VERSION "0.6.1"

NS_ :

BS_:

BU_:

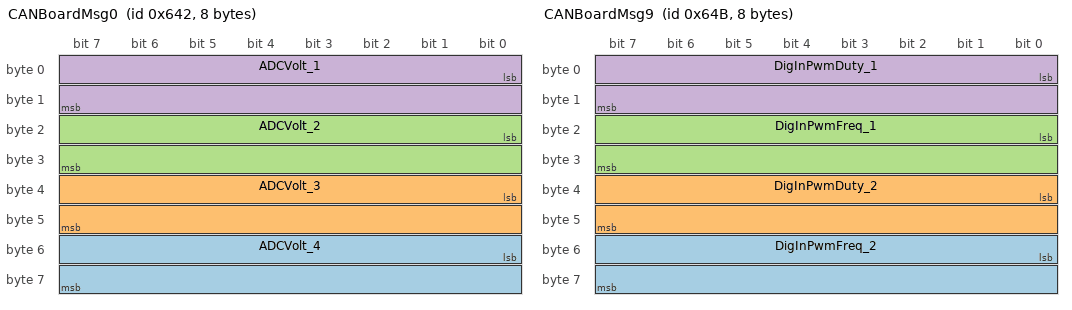
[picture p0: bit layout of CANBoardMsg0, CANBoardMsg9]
BO_ 1602 CANBoardMsg0: 8 Vector__XXX
 SG_ ADCVolt_4 : 48|16@1+ (0.001,0) [0|0] "" Vector__XXX
 SG_ ADCVolt_3 : 32|16@1+ (0.001,0) [0|0] "" Vector__XXX
 SG_ ADCVolt_2 : 16|16@1+ (0.001,0) [0|0] "" Vector__XXX
 SG_ ADCVolt_1 : 0|16@1+ (0.001,0) [0|0] "" Vector__XXX

BO_ 1603 CANBoardMsg1: 8 Vector__XXX
 SG_ BoardTemp : 48|16@1+ (1,0) [0|125] "" Vector__XXX
 SG_ ADCVolt5 : 0|16@1+ (0.001,0) [0|6] "" Vector__XXX

BO_ 1604 CANBoardMsg2: 8 Vector__XXX
 SG_ Heartbeat : 56|8@1+ (1,0) [0|255] "" Vector__XXX
 SG_ DigitalOutput_4 : 51|1@1+ (1,0) [0|0] "" Vector__XXX
 SG_ DigitalOutput_3 : 50|1@1+ (1,0) [0|0] "" Vector__XXX
 SG_ DigitalOutput_2 : 49|1@1+ (1,0) [0|0] "" Vector__XXX
 SG_ DigitalOutput_1 : 48|1@1+ (1,0) [0|0] "" Vector__XXX
 SG_ AnalogSwitch_5 : 44|1@1+ (1,0) [0|0] "" Vector__XXX
 SG_ AnalogSwitch_4 : 43|1@1+ (1,0) [0|0] "" Vector__XXX
 SG_ AnalogSwitch_3 : 42|1@1+ (1,0) [0|0] "" Vector__XXX
 SG_ AnalogSwitch_2 : 41|1@1+ (1,0) [0|0] "" Vector__XXX
 SG_ AnalogSwitch_1 : 40|1@1+ (1,0) [0|0] "" Vector__XXX
 SG_ DigitalInput_8 : 39|1@1+ (1,0) [0|0] "" Vector__XXX
 SG_ DigitalInput_7 : 38|1@1+ (1,0) [0|0] "" Vector__XXX
 SG_ DigitalInput_6 : 37|1@1+ (1,0) [0|0] "" Vector__XXX
 SG_ DigitalInput_5 : 36|1@1+ (1,0) [0|0] "" Vector__XXX
 SG_ DigitalInput_4 : 35|1@1+ (1,0) [0|0] "" Vector__XXX
 SG_ DigitalInput_3 : 34|1@1+ (1,0) [0|0] "" Vector__XXX
 SG_ DigitalInput_2 : 33|1@1+ (1,0) [0|0] "" Vector__XXX
 SG_ DigitalInput_1 : 32|1@1+ (1,0) [0|0] "" Vector__XXX
 SG_ Flash_4 : 27|1@1+ (1,0) [0|0] "" Vector__XXX
 SG_ Flash_3 : 26|1@1+ (1,0) [0|0] "" Vector__XXX
 SG_ Flash_2 : 25|1@1+ (1,0) [0|0] "" Vector__XXX
 SG_ Flash_1 : 24|1@1+ (1,0) [0|0] "" Vector__XXX
 SG_ RotarySwitch_5 : 16|4@1+ (1,0) [0|0] "" Vector__XXX
 SG_ RotarySwitch_4 : 12|4@1+ (1,0) [0|0] "" Vector__XXX
 SG_ RotarySwitch_3 : 8|4@1+ (1,0) [0|0] "" Vector__XXX
 SG_ RotarySwitch_2 : 4|4@1+ (1,0) [0|0] "" Vector__XXX
 SG_ RotarySwitch_1 : 0|4@1+ (1,0) [0|0] "" Vector__XXX

BO_ 1605 CANBoardMsg3: 8 Vector__XXX
 SG_ VirtualInput_16 : 47|1@1+ (1,0) [0|0] "" Vector__XXX
 SG_ VirtualInput_15 : 46|1@1+ (1,0) [0|0] "" Vector__XXX
 SG_ VirtualInput_14 : 45|1@1+ (1,0) [0|0] "" Vector__XXX
 SG_ VirtualInput_13 : 44|1@1+ (1,0) [0|0] "" Vector__XXX
 SG_ VirtualInput_12 : 43|1@1+ (1,0) [0|0] "" Vector__XXX
 SG_ VirtualInput_11 : 42|1@1+ (1,0) [0|0] "" Vector__XXX
 SG_ VirtualInput_10 : 41|1@1+ (1,0) [0|0] "" Vector__XXX
 SG_ VirtualInput_9 : 40|1@1+ (1,0) [0|0] "" Vector__XXX
 SG_ VirtualInput_8 : 39|1@1+ (1,0) [0|0] "" Vector__XXX
 SG_ VirtualInput_7 : 38|1@1+ (1,0) [0|0] "" Vector__XXX
 SG_ VirtualInput_6 : 37|1@1+ (1,0) [0|0] "" Vector__XXX
 SG_ VirtualInput_5 : 36|1@1+ (1,0) [0|0] "" Vector__XXX
 SG_ VirtualInput_4 : 35|1@1+ (1,0) [0|0] "" Vector__XXX
 SG_ VirtualInput_3 : 34|1@1+ (1,0) [0|0] "" Vector__XXX
 SG_ VirtualInput_2 : 33|1@1+ (1,0) [0|0] "" Vector__XXX
 SG_ VirtualInput_1 : 32|1@1+ (1,0) [0|0] "" Vector__XXX
 SG_ CANInput_32 : 31|1@1+ (1,0) [0|0] "" Vector__XXX
 SG_ CANInput_31 : 30|1@1+ (1,0) [0|0] "" Vector__XXX
 SG_ CANInput_30 : 29|1@1+ (1,0) [0|0] "" Vector__XXX
 SG_ CANInput_29 : 28|1@1+ (1,0) [0|0] "" Vector__XXX
 SG_ CANInput_28 : 27|1@1+ (1,0) [0|0] "" Vector__XXX
 SG_ CANInput_27 : 26|1@1+ (1,0) [0|0] "" Vector__XXX
 SG_ CANInput_26 : 25|1@1+ (1,0) [0|0] "" Vector__XXX
 SG_ CANInput_25 : 24|1@1+ (1,0) [0|0] "" Vector__XXX
 SG_ CANInput_24 : 23|1@1+ (1,0) [0|0] "" Vector__XXX
 SG_ CANInput_23 : 22|1@1+ (1,0) [0|0] "" Vector__XXX
 SG_ CANInput_22 : 21|1@1+ (1,0) [0|0] "" Vector__XXX
 SG_ CANInput_21 : 20|1@1+ (1,0) [0|0] "" Vector__XXX
 SG_ CANInput_20 : 19|1@1+ (1,0) [0|0] "" Vector__XXX
 SG_ CANInput_19 : 18|1@1+ (1,0) [0|0] "" Vector__XXX
 SG_ CANInput_18 : 17|1@1+ (1,0) [0|0] "" Vector__XXX
 SG_ CANInput_17 : 16|1@1+ (1,0) [0|0] "" Vector__XXX
 SG_ CANInput_16 : 15|1@1+ (1,0) [0|0] "" Vector__XXX
 SG_ CANInput_15 : 14|1@1+ (1,0) [0|0] "" Vector__XXX
 SG_ CANInput_14 : 13|1@1+ (1,0) [0|0] "" Vector__XXX
 SG_ CANInput_13 : 12|1@1+ (1,0) [0|0] "" Vector__XXX
 SG_ CANInput_12 : 11|1@1+ (1,0) [0|0] "" Vector__XXX
 SG_ CANInput_11 : 10|1@1+ (1,0) [0|0] "" Vector__XXX
 SG_ CANInput_10 : 9|1@1+ (1,0) [0|0] "" Vector__XXX
 SG_ CANInput_9 : 8|1@1+ (1,0) [0|0] "" Vector__XXX
 SG_ CANInput_8 : 7|1@1+ (1,0) [0|0] "" Vector__XXX
 SG_ CANInput_7 : 6|1@1+ (1,0) [0|0] "" Vector__XXX
 SG_ CANInput_6 : 5|1@1+ (1,0) [0|0] "" Vector__XXX
 SG_ CANInput_5 : 4|1@1+ (1,0) [0|0] "" Vector__XXX
 SG_ CANInput_4 : 3|1@1+ (1,0) [0|0] "" Vector__XXX
 SG_ CANInput_3 : 2|1@1+ (1,0) [0|0] "" Vector__XXX
 SG_ CANInput_2 : 1|1@1+ (1,0) [0|0] "" Vector__XXX
 SG_ CANInput_1 : 0|1@1+ (1,0) [0|0] "" Vector__XXX

BO_ 1606 CANBoardMsg4: 8 Vector__XXX
 SG_ ConditionResult_32 : 63|1@1+ (1,0) [0|0] "" Vector__XXX
 SG_ ConditionResult_31 : 62|1@1+ (1,0) [0|0] "" Vector__XXX
 SG_ ConditionResult_30 : 61|1@1+ (1,0) [0|0] "" Vector__XXX
 SG_ ConditionResult_29 : 60|1@1+ (1,0) [0|0] "" Vector__XXX
 SG_ ConditionResult_28 : 59|1@1+ (1,0) [0|0] "" Vector__XXX
 SG_ ConditionResult_27 : 58|1@1+ (1,0) [0|0] "" Vector__XXX
 SG_ ConditionResult_26 : 57|1@1+ (1,0) [0|0] "" Vector__XXX
 SG_ ConditionResult_25 : 56|1@1+ (1,0) [0|0] "" Vector__XXX
 SG_ ConditionResult_24 : 55|1@1+ (1,0) [0|0] "" Vector__XXX
 SG_ ConditionResult_23 : 54|1@1+ (1,0) [0|0] "" Vector__XXX
 SG_ ConditionResult_22 : 53|1@1+ (1,0) [0|0] "" Vector__XXX
 SG_ ConditionResult_21 : 52|1@1+ (1,0) [0|0] "" Vector__XXX
 SG_ ConditionResult_20 : 51|1@1+ (1,0) [0|0] "" Vector__XXX
 SG_ ConditionResult_19 : 50|1@1+ (1,0) [0|0] "" Vector__XXX
 SG_ ConditionResult_18 : 49|1@1+ (1,0) [0|0] "" Vector__XXX
 SG_ ConditionResult_17 : 48|1@1+ (1,0) [0|0] "" Vector__XXX
 SG_ ConditionResult_16 : 47|1@1+ (1,0) [0|0] "" Vector__XXX
 SG_ ConditionResult_15 : 46|1@1+ (1,0) [0|0] "" Vector__XXX
 SG_ ConditionResult_14 : 45|1@1+ (1,0) [0|0] "" Vector__XXX
 SG_ ConditionResult_13 : 44|1@1+ (1,0) [0|0] "" Vector__XXX
 SG_ ConditionResult_12 : 43|1@1+ (1,0) [0|0] "" Vector__XXX
 SG_ ConditionResult_11 : 42|1@1+ (1,0) [0|0] "" Vector__XXX
 SG_ ConditionResult_10 : 41|1@1+ (1,0) [0|0] "" Vector__XXX
 SG_ ConditionResult_9 : 40|1@1+ (1,0) [0|0] "" Vector__XXX
 SG_ ConditionResult_8 : 39|1@1+ (1,0) [0|0] "" Vector__XXX
 SG_ ConditionResult_7 : 38|1@1+ (1,0) [0|0] "" Vector__XXX
 SG_ ConditionResult_6 : 37|1@1+ (1,0) [0|0] "" Vector__XXX
 SG_ ConditionResult_5 : 36|1@1+ (1,0) [0|0] "" Vector__XXX
 SG_ ConditionResult_4 : 35|1@1+ (1,0) [0|0] "" Vector__XXX
 SG_ ConditionResult_3 : 34|1@1+ (1,0) [0|0] "" Vector__XXX
 SG_ ConditionResult_2 : 33|1@1+ (1,0) [0|0] "" Vector__XXX
 SG_ ConditionResult_1 : 32|1@1+ (1,0) [0|0] "" Vector__XXX
 SG_ CounterValue_4 : 24|8@1+ (1,0) [0|0] "" Vector__XXX
 SG_ CounterValue_3 : 16|8@1+ (1,0) [0|0] "" Vector__XXX
 SG_ CounterValue_2 : 8|8@1+ (1,0) [0|0] "" Vector__XXX
 SG_ CounterValue_1 : 0|8@1+ (1,0) [0|0] "" Vector__XXX

BO_ 1607 CANBoardMsg5: 8 Vector__XXX
 SG_ CANInputValue_2 : 32|32@1- (1,0) [0|0] "" Vector__XXX
 SG_ CANInputValue_1 : 0|32@1- (1,0) [0|0] "" Vector__XXX

BO_ 1608 CANBoardMsg6: 8 Vector__XXX
 SG_ CANInputValue_4 : 32|32@1- (1,0) [0|0] "" Vector__XXX
 SG_ CANInputValue_3 : 0|32@1- (1,0) [0|0] "" Vector__XXX

BO_ 1609 CANBoardMsg7: 8 Vector__XXX
 SG_ CANInputValue_6 : 32|32@1- (1,0) [0|0] "" Vector__XXX
 SG_ CANInputValue_5 : 0|32@1- (1,0) [0|0] "" Vector__XXX

BO_ 1610 CANBoardMsg8: 8 Vector__XXX
 SG_ CANInputValue_8 : 32|32@1- (1,0) [0|0] "" Vector__XXX
 SG_ CANInputValue_7 : 0|32@1- (1,0) [0|0] "" Vector__XXX

BO_ 1611 CANBoardMsg9: 8 Vector__XXX
 SG_ DigInPwmFreq_2 : 48|16@1+ (0.1,0) [0|6553.5] "Hz" Vector__XXX
 SG_ DigInPwmDuty_2 : 32|16@1+ (0.01,0) [0|100] "%" Vector__XXX
 SG_ DigInPwmFreq_1 : 16|16@1+ (0.1,0) [0|6553.5] "Hz" Vector__XXX
 SG_ DigInPwmDuty_1 : 0|16@1+ (0.01,0) [0|100] "%" Vector__XXX

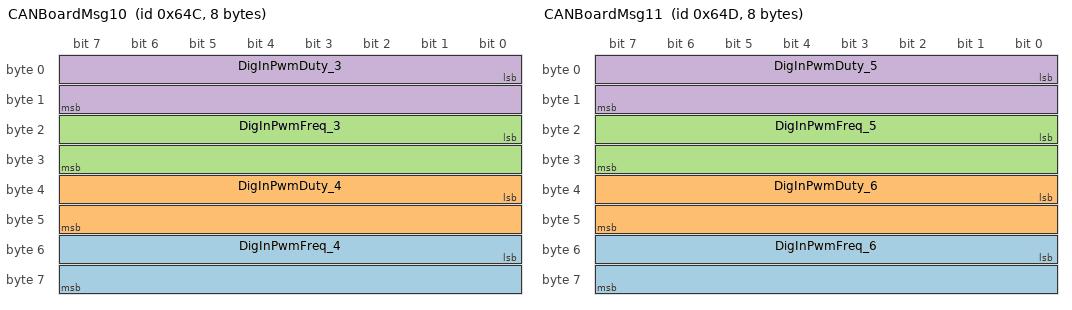
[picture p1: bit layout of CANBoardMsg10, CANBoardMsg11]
BO_ 1612 CANBoardMsg10: 8 Vector__XXX
 SG_ DigInPwmFreq_4 : 48|16@1+ (0.1,0) [0|6553.5] "Hz" Vector__XXX
 SG_ DigInPwmDuty_4 : 32|16@1+ (0.01,0) [0|100] "%" Vector__XXX
 SG_ DigInPwmFreq_3 : 16|16@1+ (0.1,0) [0|6553.5] "Hz" Vector__XXX
 SG_ DigInPwmDuty_3 : 0|16@1+ (0.01,0) [0|100] "%" Vector__XXX

BO_ 1613 CANBoardMsg11: 8 Vector__XXX
 SG_ DigInPwmFreq_6 : 48|16@1+ (0.1,0) [0|6553.5] "Hz" Vector__XXX
 SG_ DigInPwmDuty_6 : 32|16@1+ (0.01,0) [0|100] "%" Vector__XXX
 SG_ DigInPwmFreq_5 : 16|16@1+ (0.1,0) [0|6553.5] "Hz" Vector__XXX
 SG_ DigInPwmDuty_5 : 0|16@1+ (0.01,0) [0|100] "%" Vector__XXX

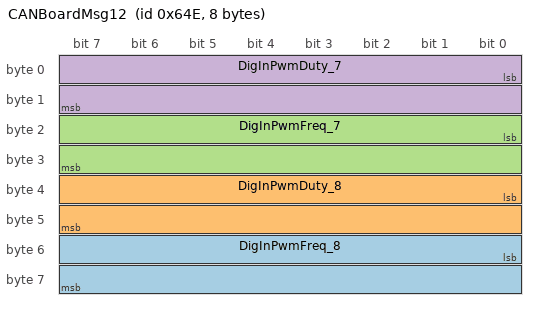
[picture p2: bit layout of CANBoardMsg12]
BO_ 1614 CANBoardMsg12: 8 Vector__XXX
 SG_ DigInPwmFreq_8 : 48|16@1+ (0.1,0) [0|6553.5] "Hz" Vector__XXX
 SG_ DigInPwmDuty_8 : 32|16@1+ (0.01,0) [0|100] "%" Vector__XXX
 SG_ DigInPwmFreq_7 : 16|16@1+ (0.1,0) [0|6553.5] "Hz" Vector__XXX
 SG_ DigInPwmDuty_7 : 0|16@1+ (0.01,0) [0|100] "%" Vector__XXX
